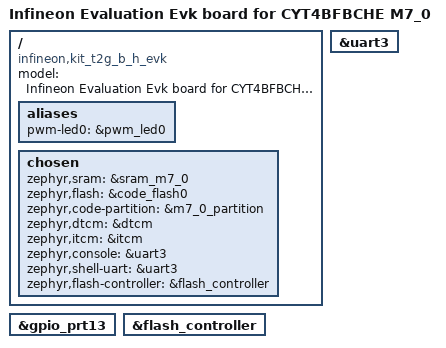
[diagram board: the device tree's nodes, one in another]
/*
 * SPDX-FileCopyrightText: <text>Copyright (c) 2026 Infineon Technologies AG,
 * or an affiliate of Infineon Technologies AG. All rights reserved.</text>
 * Copyright (c) 2026 Linumiz
 *
 * SPDX-License-Identifier: Apache-2.0
 */

/dts-v1/;
#include <arm/infineon/cat1c/traveo/cyt4bf/cyt4bf_m7.dtsi>
#include "kit_t2g_b_h_evk_cyt4bfbche_m0p-pinctrl.dtsi"
#include "kit_t2g_b_h_evk_common.dtsi"

/ {
	model = "Infineon Evaluation Evk board for CYT4BFBCHE M7_0";
	compatible = "infineon,kit_t2g_b_h_evk", "infineon,TVIIBH8M";

	aliases {
		pwm-led0 = &pwm_led0;
	};

	chosen {
		zephyr,sram = &sram_m7_0;
		zephyr,flash = &code_flash0;
		zephyr,code-partition = &m7_0_partition;
		zephyr,dtcm = &dtcm;
		zephyr,itcm = &itcm;
		zephyr,console = &uart3;
		zephyr,shell-uart = &uart3;
		zephyr,flash-controller = &flash_controller;
	};
};

&uart3 {
	status = "okay";
};

&gpio_prt13 {
	status = "okay";
};

&flash_controller {
	status = "okay";
};
